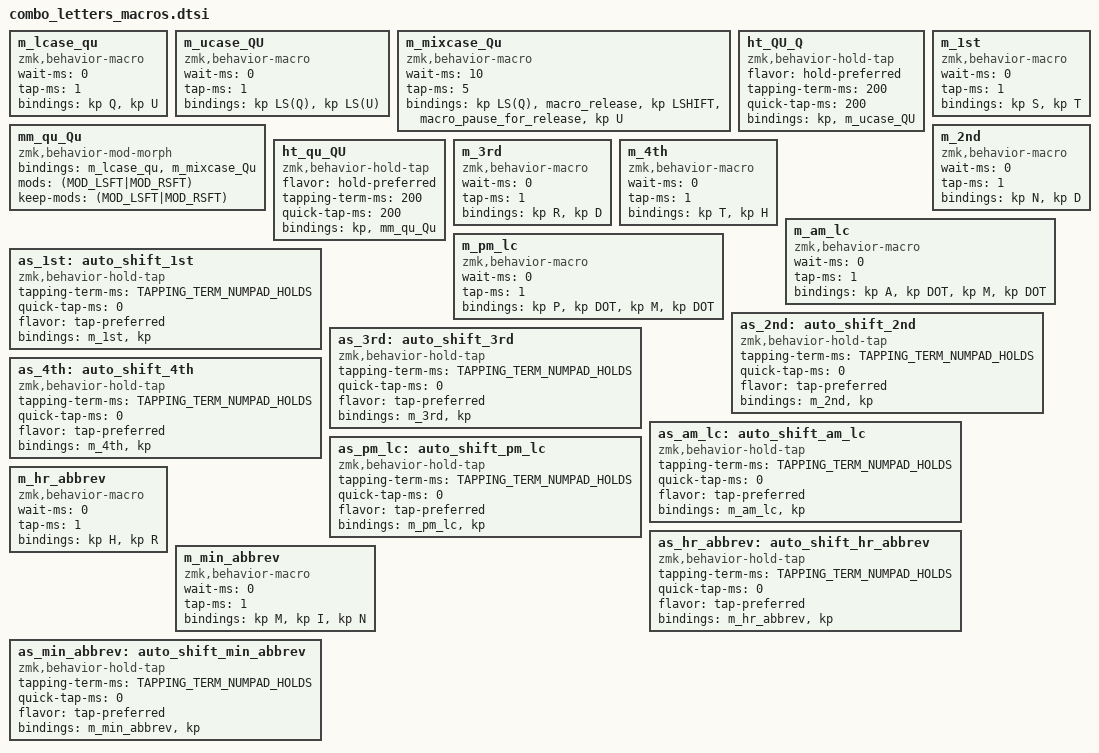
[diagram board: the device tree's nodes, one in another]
#include <dt-bindings/zmk/keys.h>


// --------------------
// ALL FOR THE QU / Q CASES

// timings - see https://zmk.dev/docs/behaviors/macros#wait-time 
    // wait-time = how long between <bindings>
    // tap-time = how long each binding is 'held'
// when timing too slow, fast typing injects other keystrokes between the Q and the U // even with ~0 it's tricky

// trying to get into key layout:
// tap: qu, shift-tap: Qu, hold: q, shift-hold: Q

// ▢ maybe the "keep-mods = ..." could help?

    // 2025-03-27 NOT USED NOW
    /*
    as_Qu: auto_shift_Qu {
      compatible = "zmk,behavior-hold-tap";
      #binding-cells = <2>;
      tapping-term-ms = <150>;
      quick-tap-ms = <0>;
      flavor = "tap-preferred";
      bindings = <&kp>, <&mm_qu_Qu>; // Hold > q, else qu|Qu
    };
    */

// Q macros: --------------------
m_lcase_qu: m_lcase_qu {
    compatible = "zmk,behavior-macro";
    wait-ms = <0>;
    tap-ms = <1>;
    #binding-cells = <0>;
    bindings = <&kp Q>, <&kp U>;
};

m_ucase_QU: m_ucase_QU {
    compatible = "zmk,behavior-macro";
    wait-ms = <0>;
    tap-ms = <1>;
    #binding-cells = <0>;
    bindings = <&kp LS(Q)>, <&kp LS(U)>;
};

m_mixcase_Qu: m_mixcase_Qu {
    compatible = "zmk,behavior-macro";
    wait-ms = <10>; // ??
    tap-ms = <5>; // ??
    #binding-cells = <0>;
    bindings =
              <&kp LS(Q)>
            , <&macro_release &kp LSHIFT>
            , <&macro_pause_for_release>
            , <&kp U>
    ;
};

// CAP layer HT --------------------
ht_QU_Q: ht_QU_Q {
    compatible = "zmk,behavior-hold-tap";
    #binding-cells = <2>;
    flavor = "hold-preferred"; // which?
    tapping-term-ms = <200>; // ▢ TODO
    quick-tap-ms = <200>; // ▢ TODO
    bindings = <&kp>, <&m_ucase_QU>; // hold for Q, tap for QU macro
};



/* OPTION 1 --------------------
 * HoldTap ⇒
 *      > Q
 *      > ModMorph
 *          > qu
 *          > Qu
 */
 // NOT working - Shift+<> ⇒ Q


// MOD MORPH for qu Qu - note not &kp based!
mm_qu_Qu: mm_qu_Qu {
    compatible = "zmk,behavior-mod-morph";
    #binding-cells = <0>;
    bindings = <&m_lcase_qu>, <&m_mixcase_Qu>;
    mods = <(MOD_LSFT|MOD_RSFT)>;
    keep-mods = <(MOD_LSFT|MOD_RSFT)>; // swallow the shift so Ø passed thru? (matter?)
  };

// HOLD TAP: Q | ModMorph(qu Qu)
ht_qu_QU: ht_qu_QU {
    compatible = "zmk,behavior-hold-tap";
    #binding-cells = <2>;
    flavor = "hold-preferred"; // which? 
    tapping-term-ms = <200>; // ▢ TODO
    quick-tap-ms = <200>; // ▢ TODO
    bindings = <&kp>, <&mm_qu_Qu>; // hold <&kp>, tap <macro "qu">
};


 /* OPTION 2 --------------------
  * ModMorph ⇒
  *     > HoldTap - q qu
  *     > HoldTap - Q Qu
  */

// ▣ 2025-03-27 Ø working - think because can't send &ref things in where simple parm [INT] expected
/*
ht_q_qu: ht_q_qu {
    compatible = "zmk,behavior-hold-tap";
    #binding-cells = <2>; // ▢ put back to 2 and put "__ Q 0" in wrapper's binding-cell?
    flavor = "hold-preferred"; // which? 
    tapping-term-ms = <200>; // ▢ TODO
    quick-tap-ms = <200>; // ▢ TODO
    //bindings = <&kp Q>, <&m_lcase_qu>; // hold = q, tap = macro(qu)
    bindings = <&kp>, <&m_lcase_qu>; // hold = q, tap = macro(qu)
};

ht_Q_Qu: ht_Q_Qu {
    compatible = "zmk,behavior-hold-tap";
    #binding-cells = <2>; // ▢ put back to 2 and put "__ Q 0" in wrapper's binding-cell?
    flavor = "hold-preferred"; // which? 
    tapping-term-ms = <200>; // ▢ TODO
    quick-tap-ms = <200>; // ▢ TODO
    //bindings = <&kp LS(Q)>, <&m_mixcase_Qu>; // hold = Q, tap = macro(Qu)
    bindings = <&kp>, <&m_mixcase_Qu>; // hold = Q, tap = macro(Qu)
};

mm_ht_qqu_QQu: mm_ht_qqu_QQu {
    compatible = "zmk,behavior-mod-morph";
    #binding-cells = <0>;
    bindings = <&ht_q_qu Q 0>, <&ht_Q_Qu LS(Q) 0>; // « seems DOES NOT WORK ∵ ___?
    mods = <(MOD_LSFT|MOD_RSFT)>;
  };
*/





// ----------------------------------------------------------------------------------------------------

// for Nth cases: st, nd, rd, th - to put on NUM shift/holds
m_1st: m_1st {
    compatible = "zmk,behavior-macro";
    wait-ms = <0>; // was 10
    tap-ms = <1>; // was 5
    #binding-cells = <0>;
    bindings = <&kp S>, <&kp T>;
};

m_2nd: m_2nd {
    compatible = "zmk,behavior-macro";
    wait-ms = <0>; // was 10
    tap-ms = <1>; // was 5
    #binding-cells = <0>;
    bindings = <&kp N>, <&kp D>;
};

m_3rd: m_3rd {
    compatible = "zmk,behavior-macro";
    wait-ms = <0>; // was 10
    tap-ms = <1>; // was 5
    #binding-cells = <0>;
    bindings = <&kp R>, <&kp D>;
};

m_4th: m_4th {
    compatible = "zmk,behavior-macro";
    wait-ms = <0>; // was 10
    tap-ms = <1>; // was 5
    #binding-cells = <0>;
    bindings = <&kp T>, <&kp H>;
};

// _a.m.
m_am_lc: m_am_lc {
    compatible = "zmk,behavior-macro";
    wait-ms = <0>; // was 10
    tap-ms = <1>; // was 5
    #binding-cells = <0>;
    bindings = <&kp A>, <&kp DOT>, <&kp M>, <&kp DOT>;
};

// _p.m.
m_pm_lc: m_pm_lc {
    compatible = "zmk,behavior-macro";
    wait-ms = <0>; // was 10
    tap-ms = <1>; // was 5
    #binding-cells = <0>;
    bindings = <&kp P>, <&kp DOT>, <&kp M>, <&kp DOT>;
};


// mod-morph shifts for these:
// ▢ TODO: see also the Q case. And make C-macros for...


// tap: the &kp, hold: the &macro for the letters...
// uses "&as_XX 0 #" in map; 0 parm for the nil macro parm; note macro is FIRST
#define TAPPING_TERM_NUMPAD_HOLDS 225

as_1st: auto_shift_1st {
    compatible = "zmk,behavior-hold-tap";
    #binding-cells = <2>;
    tapping-term-ms = <TAPPING_TERM_NUMPAD_HOLDS>;
    quick-tap-ms = <0>;
    flavor = "tap-preferred";
    bindings = <&m_1st>, <&kp>; 
};
as_2nd: auto_shift_2nd {
    compatible = "zmk,behavior-hold-tap";
    #binding-cells = <2>;
    tapping-term-ms = <TAPPING_TERM_NUMPAD_HOLDS>;
    quick-tap-ms = <0>;
    flavor = "tap-preferred";
    bindings = <&m_2nd>, <&kp>; 
};
as_3rd: auto_shift_3rd {
    compatible = "zmk,behavior-hold-tap";
    #binding-cells = <2>;
    tapping-term-ms = <TAPPING_TERM_NUMPAD_HOLDS>;
    quick-tap-ms = <0>;
    flavor = "tap-preferred";
    bindings = <&m_3rd>, <&kp>; 
};
as_4th: auto_shift_4th {
    compatible = "zmk,behavior-hold-tap";
    #binding-cells = <2>;
    tapping-term-ms = <TAPPING_TERM_NUMPAD_HOLDS>;
    quick-tap-ms = <0>;
    flavor = "tap-preferred";
    bindings = <&m_4th>, <&kp>; 
};

// holds on NUM for very common post-NUM {a.m., p.m., AM, PM}
as_am_lc: auto_shift_am_lc {
    compatible = "zmk,behavior-hold-tap";
    #binding-cells = <2>;
    tapping-term-ms = <TAPPING_TERM_NUMPAD_HOLDS>;
    quick-tap-ms = <0>;
    flavor = "tap-preferred";
    bindings = <&m_am_lc>, <&kp>; 
};

as_pm_lc: auto_shift_pm_lc {
    compatible = "zmk,behavior-hold-tap";
    #binding-cells = <2>;
    tapping-term-ms = <TAPPING_TERM_NUMPAD_HOLDS>;
    quick-tap-ms = <0>;
    flavor = "tap-preferred";
    bindings = <&m_pm_lc>, <&kp>; 
};

// ... hr
m_hr_abbrev: m_hr_abbrev {
    compatible = "zmk,behavior-macro";
    wait-ms = <0>; // was 10
    tap-ms = <1>; // was 5
    #binding-cells = <0>;
    bindings = <&kp H>, <&kp R>;
};

as_hr_abbrev: auto_shift_hr_abbrev {
    compatible = "zmk,behavior-hold-tap";
    #binding-cells = <2>;
    tapping-term-ms = <TAPPING_TERM_NUMPAD_HOLDS>;
    quick-tap-ms = <0>;
    flavor = "tap-preferred";
    bindings = <&m_hr_abbrev>, <&kp>; 
};

// ... min
m_min_abbrev: m_min_abbrev {
    compatible = "zmk,behavior-macro";
    wait-ms = <0>; // was 10
    tap-ms = <1>; // was 5
    #binding-cells = <0>;
    bindings = <&kp M>, <&kp I>, <&kp N>;
};
as_min_abbrev: auto_shift_min_abbrev {
    compatible = "zmk,behavior-hold-tap";
    #binding-cells = <2>;
    tapping-term-ms = <TAPPING_TERM_NUMPAD_HOLDS>;
    quick-tap-ms = <0>;
    flavor = "tap-preferred";
    bindings = <&m_min_abbrev>, <&kp>; 
};



/* TEMPLATE-ish

//macro
m_TBD: m_TBD {
    compatible = "zmk,behavior-macro";
    wait-ms = <0>; // was 10
    tap-ms = <1>; // was 5
    #binding-cells = <0>;
    bindings = <&kp SPACE>, <&kp LS(A)>, <&kp LS(M)>;
};
// AS that uses Macro
as_TBD: auto_shift_TBD {
    compatible = "zmk,behavior-hold-tap";
    #binding-cells = <2>;
    tapping-term-ms = <TAPPING_TERM_NUMPAD_HOLDS>;
    quick-tap-ms = <0>;
    flavor = "tap-preferred";
    bindings = <&m_TBD>, <&kp>; 
};

*/


/* UNUSED 2025-04-18

// _AM
m_am_uc: m_am_uc {
    compatible = "zmk,behavior-macro";
    wait-ms = <0>; // was 10
    tap-ms = <1>; // was 5
    #binding-cells = <0>;
    bindings = <&kp SPACE>, <&kp LS(A)>, <&kp LS(M)>;
};

as_am_uc: auto_shift_am_uc {
    compatible = "zmk,behavior-hold-tap";
    #binding-cells = <2>;
    tapping-term-ms = <TAPPING_TERM_NUMPAD_HOLDS>;
    quick-tap-ms = <0>;
    flavor = "tap-preferred";
    bindings = <&m_am_uc>, <&kp>; 
};

// _PM
m_pm_uc: m_pm_uc {
    compatible = "zmk,behavior-macro";
    wait-ms = <0>; // was 10
    tap-ms = <1>; // was 5
    #binding-cells = <0>;
    bindings = <&kp SPACE>, <&kp LS(P)>, <&kp LS(M)>;
};

as_pm_uc: auto_shift_pm_uc {
    compatible = "zmk,behavior-hold-tap";
    #binding-cells = <2>;
    tapping-term-ms = <TAPPING_TERM_NUMPAD_HOLDS>;
    quick-tap-ms = <0>;
    flavor = "tap-preferred";
    bindings = <&m_pm_uc>, <&kp>; 
};

// minutes
m_minutes: m_minutes {
    compatible = "zmk,behavior-macro";
    wait-ms = <0>; // was 10
    tap-ms = <1>; // was 5
    #binding-cells = <0>;
    bindings = <&kp SPACE>, <&kp M>, <&kp I>, <&kp N>, <&kp U>, <&kp T>, <&kp E>, <&kp S>;
};

as_minutes: auto_shift_minutes {
    compatible = "zmk,behavior-hold-tap";
    #binding-cells = <2>;
    tapping-term-ms = <TAPPING_TERM_NUMPAD_HOLDS>;
    quick-tap-ms = <0>;
    flavor = "tap-preferred";
    bindings = <&m_minutes>, <&kp>; 
};
*/
